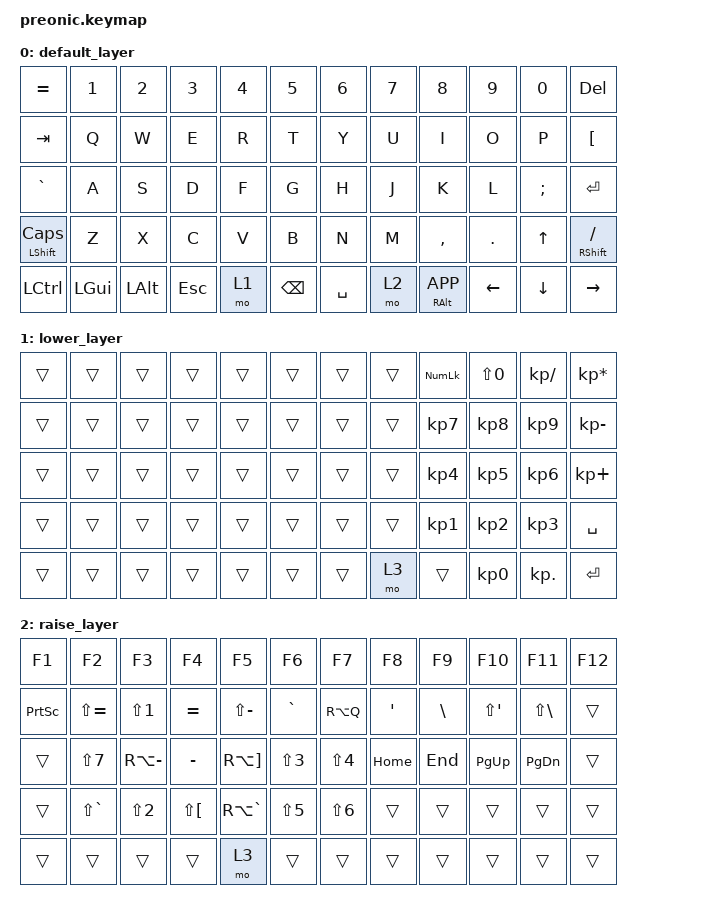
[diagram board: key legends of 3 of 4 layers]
/*
 * Copyright (c) 2021 The ZMK Contributors
 *
 * SPDX-License-Identifier: MIT
 */

#include <behaviors.dtsi>
#include <dt-bindings/zmk/keys.h>
#include <dt-bindings/zmk/bt.h>
#include <dt-bindings/zmk/ext_power.h>
#include <dt-bindings/zmk/outputs.h>

/ {
    keymap {
        compatible =  "zmk,keymap" ;

        default_layer {
            //  -------------------------------------------------------------------------------------------------
            // |  GRAV |  1   |  2   |  3   |  4    |  5     |   6     |  7     |  8   |  9    |   0   |    |
            // |  TAB  |  Q   |  W   |  E   |  R    |  T     |   Y     |  U     |  I   |  O    |   P   | DEL    |
            // |  ESC  |  A   |  S   |  D   |  F    |  G     |   H     |  J     |  K   |  L    |   ;   |  '     |
            // | SHIFT |  Z   |  X   |  C   |  V    |  B     |   N     |  M     |  ,   |  .    |   /   | RET    |
            // |  LCTL | LGUI | LALT | ESC  | LOWER | BSPC   |  SPACE  |  RAISE |  |  LEFT |  DOWN | RIGHT  |
            bindings = <
   &kp EQUAL       &kp N1   &kp N2   &kp N3    &kp N4   &kp N5    &kp N6     &kp N7  &kp N8           &kp N9    &kp N0    &kp DEL
   &kp TAB         &kp Q    &kp W    &kp E     &kp R    &kp T     &kp Y      &kp U   &kp I            &kp O     &kp P     &kp LBKT
   &kp GRAVE       &kp A    &kp S    &kp D     &kp F    &kp G     &kp H      &kp J   &kp K            &kp L     &kp SEMI  &kp RET
   &mt LSHFT CLCK  &kp Z    &kp X    &kp C     &kp V    &kp B     &kp N      &kp M   &kp COMMA        &kp DOT   &kp UP    &mt RSHFT FSLH
   &kp LCTRL       &kp LGUI &kp LALT &kp ESC   &mo 1    &kp BSPC  &kp SPACE  &mo 2   &mt RALT K_APP   &kp LEFT  &kp DOWN  &kp RIGHT
            >;

        };
        
        lower_layer {
             // ------------------------------------------------------------------------------------------
            // |   ~   |  !   |  @   |  #   |  $   |  %   |   ^   |   &   |   *  |  (   |   )   | BSPC  |
            // |   ~   |  !   |  @   |  #   |  $   |  %   |   ^   |   &   |   *  |  (   |   )   | DEL   |
            // |  DEL  |  F1  |  F2  |  F3  |  F4  |  F5  |  F6   |   -   |   +  |  [   |   ]   |  |    |
            // |       |  F7  |  F8  |  F9  |  F10 |  F11 |  F12  |       | LCTL | HOME |  END  |       |
            // | LALT  |      |      |      |      |      |       |       | NEXT | VOL- | VOL+  | PLAY  |
            bindings = <
  &trans  &trans  &trans   &trans  &trans   &trans  &trans  &trans   &kp KP_NUM   &kp LS(N0)   &kp KP_DIVIDE   &kp KP_MULTIPLY
  &trans  &trans  &trans   &trans  &trans   &trans  &trans  &trans   &kp KP_N7    &kp KP_N8    &kp KP_N9       &kp KP_MINUS  
  &trans  &trans  &trans   &trans  &trans   &trans  &trans  &trans   &kp KP_N4    &kp KP_N5    &kp KP_N6       &kp KP_PLUS  
  &trans  &trans  &trans   &trans  &trans   &trans  &trans  &trans   &kp KP_N1    &kp KP_N2    &kp KP_N3       &kp SPACE  
  &trans  &trans  &trans   &trans  &trans   &trans  &trans  &mo 3    &trans       &kp KP_N0    &kp KP_DOT      &kp RET     
            >;
        };

      raise_layer {
            // -------------------------------------------------------------------------------------------
            // |   `   |  1   |  2   |  3   |  4   |   5   |   6   |   7   |   8  |  9   |   0   | BSPC  |
            // |   `   |  1   |  2   |  3   |  4   |   5   |   6   |   7   |   8  |  9   |   0   | DEL   |
            // |  DEL  |  F1  |  F2  |  F3  |  F4  |  F5   |  F6   |   -   |   =  |  [   |   ]   |  \    |
            // |       |  F7  |  F8  |  F9  |  F10 |  F11  |  F12  |   #   |   \  | PGUP |  PGDN |       |
            // |       |      |      |      |      | SHIFT |       |       | NEXT | VOL- |  VOL+ | PLAY  |
            bindings = <
   &kp F1     &kp F2         &kp F3        &kp F4        &kp F5         &kp F6      &kp F7      &kp F8    &kp F9     &kp F10       &kp F11        &kp F12   
   &kp PSCRN  &kp LS(EQUAL)  &kp LS(N1)    &kp EQUAL     &kp LS(MINUS)  &kp GRAVE   &kp RA(Q)   &kp SQT   &kp BSLH   &kp LS(SQT)   &kp LS(BSLH)   &trans
   &trans     &kp LS(N7)     &kp RA(MINUS) &kp MINUS     &kp RA(RBKT)   &kp LS(N3)  &kp LS(N4)  &kp HOME  &kp END    &kp PG_UP     &kp PG_DN      &trans
   &trans     &kp LS(GRAVE)  &kp LS(N2)    &kp LS(LBKT)  &kp RA(GRAVE)  &kp LS(N5)  &kp LS(N6)  &trans    &trans     &trans        &trans         &trans
   &trans     &trans         &trans        &trans        &mo 3          &trans      &trans      &trans    &trans     &trans        &trans         &trans
            >;
        };

        adjust_layer {
            // -------------------------------------------------------------------------------------------
            // |   `   |  1   |  2   |  3   |  4   |   5   |   6   |   7   |   8  |  9   |   0   | BSPC  |
            // |   `   |  1   |  2   |  3   |  4   |   5   |   6   |   7   |   8  |  9   |   0   | DEL   |
            // |  DEL  |  F1  |  F2  |  F3  |  F4  |  F5   |  F6   |   -   |   =  |  [   |   ]   |  \    |
            // |       |  F7  |  F8  |  F9  |  F10 |  F11  |  F12  |   #   |   \  | PGUP |  PGDN |       |
            // |       |      |      |      |      | SHIFT |       |       | NEXT | VOL- |  VOL+ | PLAY  |
                        bindings = <
   &none   &none      &none        &none        &none            &none   &none        &none        &none         &none         &none         &none
   &trans  &none      &none        &none        &none            &none   &bootloader  &bt BT_CLR   &bt BT_SEL 0  &bt BT_SEL 1  &bt BT_SEL 2  &bt BT_SEL 3 
   &trans  &kp C_MUTE &kp C_VOL_DN &kp C_VOL_UP &kp C_PP         &none   &sys_reset   &trans       &trans        &trans        &trans        &trans       
   &trans  &trans     &trans       &trans       &none            &none   &trans       &trans       &trans        &trans        &trans        &trans       
   &trans  &trans     &trans       &trans       &trans           &trans               &trans       &trans        &trans        &trans        &trans      
            >;
        }; 
        
        
    };
};
